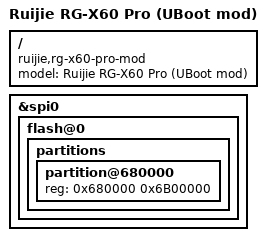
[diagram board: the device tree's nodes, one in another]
// SPDX-License-Identifier: (GPL-2.0 OR MIT)

/dts-v1/;


#include "mt7986a-ruijie-rg-x60-pro.dts"

/ {
	model = "Ruijie RG-X60 Pro (UBoot mod)";
	compatible = "ruijie,rg-x60-pro-mod", "mediatek,mt7986a";
};

&spi0 {
	flash@0 {
		partitions {
			partition@680000 {
				reg = <0x680000 0x6B00000>;
			};
		};
	};
};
